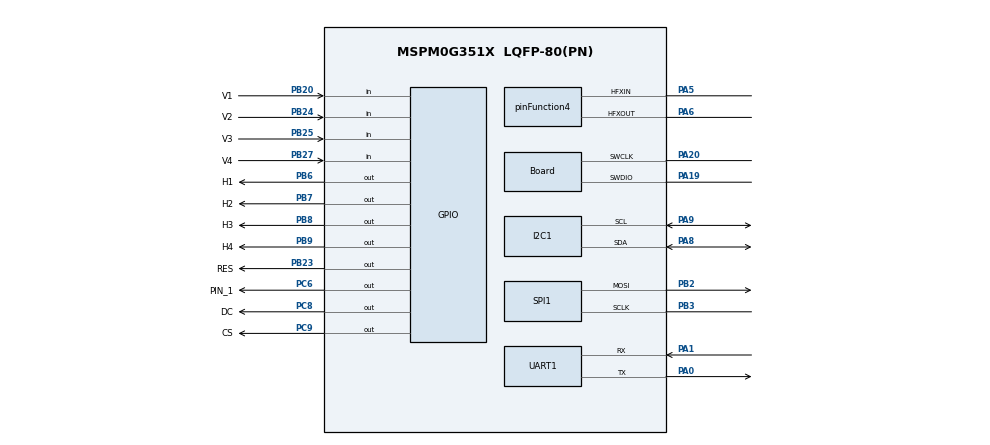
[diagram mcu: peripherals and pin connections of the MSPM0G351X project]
/**
 * @cliArgs --device "MSPM0G351X" --part "Default" --package "LQFP-80(PN)" --product "mspm0_sdk@2.08.00.03"
 * @versions {"tool":"1.25.0+4268"}
 */

/**
 * Import the modules used in this configuration.
 */
const GPIO   = scripting.addModule("/ti/driverlib/GPIO", {}, false);
const GPIO1  = GPIO.addInstance();
const GPIO2  = GPIO.addInstance();
const GPIO3  = GPIO.addInstance();
const I2C    = scripting.addModule("/ti/driverlib/I2C", {}, false);
const I2C1   = I2C.addInstance();
const SPI    = scripting.addModule("/ti/driverlib/SPI", {}, false);
const SPI1   = SPI.addInstance();
const SYSCTL = scripting.addModule("/ti/driverlib/SYSCTL");
const TIMER  = scripting.addModule("/ti/driverlib/TIMER", {}, false);
const TIMER1 = TIMER.addInstance();
const TRNG   = scripting.addModule("/ti/driverlib/TRNG");
const UART   = scripting.addModule("/ti/driverlib/UART", {}, false);
const UART1  = UART.addInstance();

/**
 * Write custom configuration values to the imported modules.
 */
const divider2       = system.clockTree["HFCLK4MFPCLKDIV"];
divider2.divideValue = 10;

const divider9       = system.clockTree["UDIV"];
divider9.divideValue = 2;

const gate7  = system.clockTree["MFCLKGATE"];
gate7.enable = true;

const gate8  = system.clockTree["MFPCLKGATE"];
gate8.enable = true;

const multiplier2         = system.clockTree["PLL_QDIV"];
multiplier2.multiplyValue = 4;

const mux4       = system.clockTree["EXHFMUX"];
mux4.inputSelect = "EXHFMUX_XTAL";

const mux8       = system.clockTree["HSCLKMUX"];
mux8.inputSelect = "HSCLKMUX_SYSPLL0";

const mux10       = system.clockTree["MFPCLKMUX"];
mux10.inputSelect = "MFPCLKMUX_HFCLK";

const mux12       = system.clockTree["SYSPLLMUX"];
mux12.inputSelect = "zSYSPLLMUX_HFCLK";

const pinFunction4                        = system.clockTree["HFXT"];
pinFunction4.inputFreq                    = 40;
pinFunction4.enable                       = true;
pinFunction4.HFXTStartup                  = 10;
pinFunction4.peripheral.$assign           = "SYSCTL";
pinFunction4.peripheral.hfxInPin.$assign  = "PA5";
pinFunction4.peripheral.hfxOutPin.$assign = "PA6";

const pinFunction6     = system.clockTree["LFXT"];
pinFunction6.inputFreq = 32.768;

GPIO1.$name                         = "OLED";
GPIO1.associatedPins.create(3);
GPIO1.associatedPins[0].$name       = "RES";
GPIO1.associatedPins[0].pin.$assign = "PB23";
GPIO1.associatedPins[1].$name       = "CS";
GPIO1.associatedPins[1].pin.$assign = "PC9";
GPIO1.associatedPins[2].$name       = "DC";
GPIO1.associatedPins[2].pin.$assign = "PC8";

const Board                       = scripting.addModule("/ti/driverlib/Board", {}, false);
Board.peripheral.$assign          = "DEBUGSS";
Board.peripheral.swclkPin.$assign = "PA20";
Board.peripheral.swdioPin.$assign = "PA19";

GPIO2.$name                              = "KeyBoard";
GPIO2.port                               = "PORTB";
GPIO2.associatedPins.create(8);
GPIO2.associatedPins[0].$name            = "H1";
GPIO2.associatedPins[0].assignedPin      = "6";
GPIO2.associatedPins[0].pin.$assign      = "PB6";
GPIO2.associatedPins[1].$name            = "H2";
GPIO2.associatedPins[1].assignedPin      = "7";
GPIO2.associatedPins[1].pin.$assign      = "PB7";
GPIO2.associatedPins[2].$name            = "H3";
GPIO2.associatedPins[2].assignedPin      = "8";
GPIO2.associatedPins[2].pin.$assign      = "PB8";
GPIO2.associatedPins[3].$name            = "H4";
GPIO2.associatedPins[3].assignedPin      = "9";
GPIO2.associatedPins[3].pin.$assign      = "PB9";
GPIO2.associatedPins[4].$name            = "V1";
GPIO2.associatedPins[4].direction        = "INPUT";
GPIO2.associatedPins[4].internalResistor = "PULL_UP";
GPIO2.associatedPins[4].assignedPin      = "20";
GPIO2.associatedPins[4].pin.$assign      = "PB20";
GPIO2.associatedPins[5].$name            = "V2";
GPIO2.associatedPins[5].direction        = "INPUT";
GPIO2.associatedPins[5].internalResistor = "PULL_UP";
GPIO2.associatedPins[5].assignedPin      = "24";
GPIO2.associatedPins[5].pin.$assign      = "PB24";
GPIO2.associatedPins[6].$name            = "V3";
GPIO2.associatedPins[6].direction        = "INPUT";
GPIO2.associatedPins[6].internalResistor = "PULL_UP";
GPIO2.associatedPins[6].assignedPin      = "25";
GPIO2.associatedPins[6].pin.$assign      = "PB25";
GPIO2.associatedPins[7].$name            = "V4";
GPIO2.associatedPins[7].direction        = "INPUT";
GPIO2.associatedPins[7].internalResistor = "PULL_UP";
GPIO2.associatedPins[7].assignedPin      = "27";
GPIO2.associatedPins[7].pin.$assign      = "PB27";

GPIO3.$name                          = "LED";
GPIO3.port                           = "PORTC";
GPIO3.associatedPins[0].$name        = "PIN_1";
GPIO3.associatedPins[0].assignedPin  = "6";
GPIO3.associatedPins[0].initialValue = "SET";
GPIO3.associatedPins[0].pin.$assign  = "PC6";

I2C1.$name                     = "I2C_0";
I2C1.basicEnableController     = true;
I2C1.timeoutACount             = 100;
I2C1.peripheral.$assign        = "I2C0";
I2C1.peripheral.sdaPin.$assign = "PA8";
I2C1.peripheral.sclPin.$assign = "PA9";
I2C1.sdaPinConfig.$name        = "ti_driverlib_gpio_GPIOPinGeneric1";
I2C1.sdaPinConfig.enableConfig = true;
I2C1.sclPinConfig.$name        = "ti_driverlib_gpio_GPIOPinGeneric5";
I2C1.sclPinConfig.enableConfig = true;

SPI1.$name                      = "SPI_0";
SPI1.targetBitRate              = 10000000;
SPI1.frameFormat                = "MOTO3";
SPI1.direction                  = "PICO";
SPI1.sclkPinConfig.$name        = "ti_driverlib_gpio_GPIOPinGeneric3";
SPI1.mosiPinConfig.$name        = "ti_driverlib_gpio_GPIOPinGeneric4";
SPI1.peripheral.$assign         = "SPI0";
SPI1.peripheral.sclkPin.$assign = "PB3";
SPI1.peripheral.mosiPin.$assign = "PB2";

SYSCTL.forceDefaultClkConfig = true;
SYSCTL.clockTreeEn           = true;

TIMER1.$name              = "TIMER_0";
TIMER1.timerPeriod        = "5 ms";
TIMER1.timerClkPrescale   = 8;
TIMER1.timerClkDiv        = 8;
TIMER1.enableShadowLoad   = true;
TIMER1.interrupts         = ["ZERO"];
TIMER1.peripheral.$assign = "TIMA0";

TRNG.clockDivider = "DL_TRNG_CLOCK_DIVIDE_8";

UART1.$name                    = "UART_0";
UART1.enabledInterrupts        = ["RX"];
UART1.peripheral.$assign       = "UART0";
UART1.peripheral.rxPin.$assign = "PA1";
UART1.peripheral.txPin.$assign = "PA0";
UART1.txPinConfig.$name        = "ti_driverlib_gpio_GPIOPinGeneric0";
UART1.rxPinConfig.$name        = "ti_driverlib_gpio_GPIOPinGeneric2";

const ProjectConfig              = scripting.addModule("/ti/project_config/ProjectConfig", {}, false);
ProjectConfig.migrationCondition = true;
